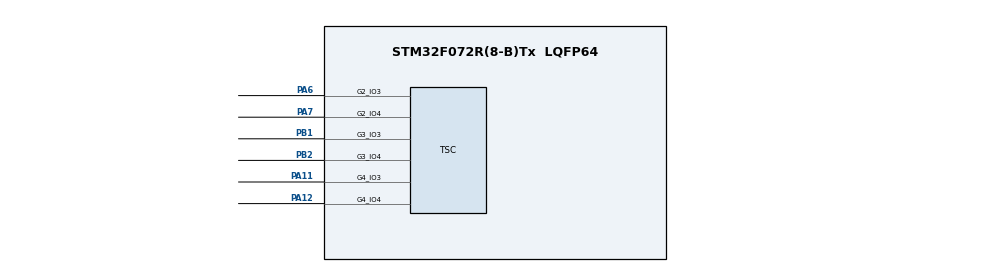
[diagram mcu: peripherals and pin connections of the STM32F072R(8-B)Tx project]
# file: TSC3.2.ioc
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Mcu.Family=STM32F0
Mcu.Name=STM32F072R(8-B)Tx
Mcu.Package=LQFP64
PA11.Mode=G4_IO3-Sampling
PA11.Signal=TSC_G4_IO3
PA12.Mode=G4_IO4-Channel
PA12.Signal=TSC_G4_IO4
PA6.Mode=G2_IO3-Sampling
PA6.Signal=TSC_G2_IO3
PA7.Mode=G2_IO4-Channel
PA7.Signal=TSC_G2_IO4
PB1.Mode=G3_IO3-Sampling
PB1.Signal=TSC_G3_IO3
PB2.Mode=G3_IO4-Channel
PB2.Signal=TSC_G3_IO4
ProjectManager.HeapSize=0x200
ProjectManager.StackSize=0x400
ProjectManager.TargetToolchain=STM32CubeIDE
TOUCHSENSING.IO_TOUCHKEY_B1=G2_IO4
TOUCHSENSING.IO_TOUCHKEY_B2=G3_IO4
TOUCHSENSING.IO_TOUCHKEY_B3=G4_IO4
TOUCHSENSING.TSLPRM_SENSORS_DATAS=TSLPRM_TOTAL_TOUCHKEYS_B 1 3 
TOUCHSENSING.TSLPRM_TOTAL_TOUCHKEYS_B=3
TSC.ChannelIOs-G2_IO4-Channel=TSC_GROUP2_IO4
TSC.ChannelIOs-G3_IO4-Channel=TSC_GROUP3_IO4
TSC.ChannelIOs-G4_IO4-Channel=TSC_GROUP4_IO4
TSC.SamplingIOs-G2_IO3-Sampling=TSC_GROUP2_IO3
TSC.SamplingIOs-G3_IO3-Sampling=TSC_GROUP3_IO3
TSC.SamplingIOs-G4_IO3-Sampling=TSC_GROUP4_IO3
VP_TOUCHSENSING_VS_TOUCHSENSING.Mode=TouchSensing_Enabled
board=custom

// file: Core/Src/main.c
/* USER CODE BEGIN Header */
/**
  ******************************************************************************
  * @file           : main.c
  * @brief          : Main program body
  ******************************************************************************
  * @attention
  *
  * Copyright (c) 2025 STMicroelectronics.
  * All rights reserved.
  *
  * This software is licensed under terms that can be found in the LICENSE file
  * in the root directory of this software component.
  * If no LICENSE file comes with this software, it is provided AS-IS.
  *
  ******************************************************************************
  */
/* USER CODE END Header */
#include "main.h"
#include "touchsensing.h"

TSC_HandleTypeDef htsc;

void SystemClock_Config(void);
static void MX_GPIO_Init(void);
static void MX_TSC_Init(void);

int main(void)
{

  /* MCU Configuration--------------------------------------------------------*/

  /* Reset of all peripherals, Initializes the Flash interface and the Systick. */
  HAL_Init();

  /* Configure the system clock */
  SystemClock_Config();

  /* Initialize all configured peripherals */
  MX_GPIO_Init();
  MX_TSC_Init();
  MX_TOUCHSENSING_Init();
  /* USER CODE BEGIN 2 */
  tsl_user_Init();
  /* USER CODE END 2 */

  /* Infinite loop */
  /* USER CODE BEGIN WHILE */
  while (1)
  {
	  tsl_user_Exec();
    /* USER CODE END WHILE */

  }
}

void SystemClock_Config(void)
{
  RCC_OscInitTypeDef RCC_OscInitStruct = {0};
  RCC_ClkInitTypeDef RCC_ClkInitStruct = {0};

  /** Initializes the RCC Oscillators according to the specified parameters
  * in the RCC_OscInitTypeDef structure.
  */
  RCC_OscInitStruct.OscillatorType = RCC_OSCILLATORTYPE_HSI;
  RCC_OscInitStruct.HSIState = RCC_HSI_ON;
  RCC_OscInitStruct.HSICalibrationValue = RCC_HSICALIBRATION_DEFAULT;
  RCC_OscInitStruct.PLL.PLLState = RCC_PLL_NONE;
  if (HAL_RCC_OscConfig(&RCC_OscInitStruct) != HAL_OK)
  {
    Error_Handler();
  }

  /** Initializes the CPU, AHB and APB buses clocks
  */
  RCC_ClkInitStruct.ClockType = RCC_CLOCKTYPE_HCLK|RCC_CLOCKTYPE_SYSCLK
                              |RCC_CLOCKTYPE_PCLK1;
  RCC_ClkInitStruct.SYSCLKSource = RCC_SYSCLKSOURCE_HSI;
  RCC_ClkInitStruct.AHBCLKDivider = RCC_SYSCLK_DIV1;
  RCC_ClkInitStruct.APB1CLKDivider = RCC_HCLK_DIV1;

  if (HAL_RCC_ClockConfig(&RCC_ClkInitStruct, FLASH_LATENCY_0) != HAL_OK)
  {
    Error_Handler();
  }
}

static void MX_TSC_Init(void)
{

  /** Configure the TSC peripheral
  */
  htsc.Instance = TSC;
  htsc.Init.CTPulseHighLength = TSC_CTPH_2CYCLES;
  htsc.Init.CTPulseLowLength = TSC_CTPL_2CYCLES;
  htsc.Init.SpreadSpectrum = DISABLE;
  htsc.Init.SpreadSpectrumDeviation = 1;
  htsc.Init.SpreadSpectrumPrescaler = TSC_SS_PRESC_DIV1;
  htsc.Init.PulseGeneratorPrescaler = TSC_PG_PRESC_DIV4;
  htsc.Init.MaxCountValue = TSC_MCV_8191;
  htsc.Init.IODefaultMode = TSC_IODEF_OUT_PP_LOW;
  htsc.Init.SynchroPinPolarity = TSC_SYNC_POLARITY_FALLING;
  htsc.Init.AcquisitionMode = TSC_ACQ_MODE_NORMAL;
  htsc.Init.MaxCountInterrupt = DISABLE;
  htsc.Init.ChannelIOs = TSC_GROUP2_IO4|TSC_GROUP3_IO4|TSC_GROUP4_IO4;
  htsc.Init.ShieldIOs = 0;
  htsc.Init.SamplingIOs = TSC_GROUP2_IO3|TSC_GROUP3_IO3|TSC_GROUP4_IO3;
  if (HAL_TSC_Init(&htsc) != HAL_OK)
  {
    Error_Handler();
  }

}

static void MX_GPIO_Init(void)
{

  /* GPIO Ports Clock Enable */
  __HAL_RCC_GPIOA_CLK_ENABLE();
  __HAL_RCC_GPIOB_CLK_ENABLE();

}

void Error_Handler(void)
{
  __disable_irq();
  while (1)
  {
  }
}
